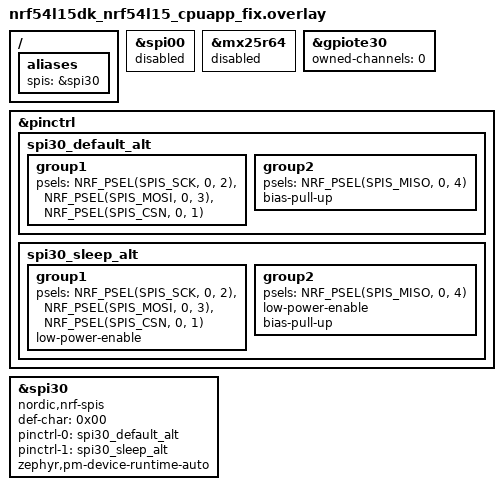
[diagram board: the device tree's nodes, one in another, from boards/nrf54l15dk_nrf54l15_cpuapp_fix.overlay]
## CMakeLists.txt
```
#
# Copyright (c) 2026 Nordic Semiconductor ASA
#
# SPDX-License-Identifier: LicenseRef-Nordic-5-Clause
#

cmake_minimum_required(VERSION 3.20.0)

find_package(Zephyr REQUIRED HINTS $ENV{ZEPHYR_BASE})

project(spis_floating)

target_sources(app PRIVATE src/main.c)
```

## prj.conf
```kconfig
CONFIG_SPI=y
CONFIG_SPI_PERIPHERAL=y

CONFIG_PM=y
CONFIG_PM_DEVICE=y
CONFIG_PM_DEVICE_RUNTIME=y

CONFIG_ASSERT=y

CONFIG_LOG=n
CONFIG_CONSOLE=n
CONFIG_UART_CONSOLE=n
CONFIG_SERIAL=n
CONFIG_BOOT_BANNER=n
CONFIG_NCS_BOOT_BANNER=n
```

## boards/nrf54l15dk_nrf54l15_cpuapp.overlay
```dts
/*
 * Copyright (c) 2026 Nordic Semiconductor ASA
 *
 * SPDX-License-Identifier: LicenseRef-Nordic-5-Clause
 */

/ {
	aliases {
		spis = &spi30;
	};
};

/* Disable mx25r64. */
&spi00 {
	status = "disabled";
};

&mx25r64 {
	status = "disabled";
};

&gpiote30 {
	status = "okay";
	owned-channels = <0>;
};

&pinctrl {
	spi30_default_alt: spi30_default_alt {
		group1 {
			psels = <NRF_PSEL(SPIS_SCK, 0, 2)>,	/* UART0_RTS */
				<NRF_PSEL(SPIS_MOSI, 0, 3)>,	/* UART0_CTS */
				<NRF_PSEL(SPIS_MISO, 0, 4)>,
				<NRF_PSEL(SPIS_CSN, 0, 1)>;	/* UART0_RX */
		};
	};

	spi30_sleep_alt: spi30_sleep_alt {
		group1 {
			psels = <NRF_PSEL(SPIS_SCK, 0, 2)>,
				<NRF_PSEL(SPIS_MOSI, 0, 3)>,
				<NRF_PSEL(SPIS_MISO, 0, 4)>,
				<NRF_PSEL(SPIS_CSN, 0, 1)>;
			low-power-enable;
		};
	};
};

&spi30 {
	compatible = "nordic,nrf-spis";
	status = "okay";
	def-char = <0x00>;
	pinctrl-0 = <&spi30_default_alt>;
	pinctrl-1 = <&spi30_sleep_alt>;
	pinctrl-names = "default", "sleep";
	/delete-property/ rx-delay-supported;
	/delete-property/ rx-delay;
	zephyr,pm-device-runtime-auto;
};
```

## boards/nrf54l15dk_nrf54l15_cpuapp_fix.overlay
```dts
/*
 * Copyright (c) 2026 Nordic Semiconductor ASA
 *
 * SPDX-License-Identifier: LicenseRef-Nordic-5-Clause
 */

/ {
	aliases {
		spis = &spi30;
	};
};

/* Disable mx25r64. */
&spi00 {
	status = "disabled";
};

&mx25r64 {
	status = "disabled";
};

&gpiote30 {
	status = "okay";
	owned-channels = <0>;
};

&pinctrl {
	spi30_default_alt: spi30_default_alt {
		group1 {
			psels = <NRF_PSEL(SPIS_SCK, 0, 2)>,	/* UART0_RTS */
				<NRF_PSEL(SPIS_MOSI, 0, 3)>,	/* UART0_CTS */
				<NRF_PSEL(SPIS_CSN, 0, 1)>;	/* UART0_RX */
		};

		group2 {
			psels = <NRF_PSEL(SPIS_MISO, 0, 4)>;
			bias-pull-up;
		};
	};

	spi30_sleep_alt: spi30_sleep_alt {
		group1 {
			psels = <NRF_PSEL(SPIS_SCK, 0, 2)>,
				<NRF_PSEL(SPIS_MOSI, 0, 3)>,
				<NRF_PSEL(SPIS_CSN, 0, 1)>;
			low-power-enable;
		};

		group2 {
			psels = <NRF_PSEL(SPIS_MISO, 0, 4)>;
			low-power-enable;
			bias-pull-up;
		};
	};
};

&spi30 {
	compatible = "nordic,nrf-spis";
	status = "okay";
	def-char = <0x00>;
	pinctrl-0 = <&spi30_default_alt>;
	pinctrl-1 = <&spi30_sleep_alt>;
	pinctrl-names = "default", "sleep";
	/delete-property/ rx-delay-supported;
	/delete-property/ rx-delay;
	zephyr,pm-device-runtime-auto;
};
```

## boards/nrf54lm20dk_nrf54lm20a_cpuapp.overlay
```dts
/*
 * Copyright (c) 2026 Nordic Semiconductor ASA
 *
 * SPDX-License-Identifier: LicenseRef-Nordic-5-Clause
 */

/ {
	aliases {
		spis = &spi30;
	};
};

/* Disable mx25r64. */
&spi00 {
	status = "disabled";
};

&mx25r64 {
	status = "disabled";
};

&gpiote30 {
	status = "okay";
	owned-channels = <0>;
};

&pinctrl {
	spi30_default_alt: spi30_default_alt {
		group1 {
			psels = <NRF_PSEL(SPIS_SCK, 0, 8)>,	/* UART0_RTS */
				<NRF_PSEL(SPIS_MOSI, 0, 9)>,	/* UART0_CTS */
				<NRF_PSEL(SPIS_MISO, 0, 1)>,
				<NRF_PSEL(SPIS_CSN, 0, 7)>;	/* UART0_RX */
		};
	};

	spi30_sleep_alt: spi30_sleep_alt {
		group1 {
			psels = <NRF_PSEL(SPIS_SCK, 0, 8)>,
				<NRF_PSEL(SPIS_MOSI, 0, 9)>,
				<NRF_PSEL(SPIS_MISO, 0, 1)>,
				<NRF_PSEL(SPIS_CSN, 0, 7)>;
			low-power-enable;
		};
	};
};

&spi30 {
	compatible = "nordic,nrf-spis";
	status = "okay";
	def-char = <0x00>;
	pinctrl-0 = <&spi30_default_alt>;
	pinctrl-1 = <&spi30_sleep_alt>;
	pinctrl-names = "default", "sleep";
	/delete-property/ rx-delay-supported;
	/delete-property/ rx-delay;
	zephyr,pm-device-runtime-auto;
};
```

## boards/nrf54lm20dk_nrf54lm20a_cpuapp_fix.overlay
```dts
/*
 * Copyright (c) 2026 Nordic Semiconductor ASA
 *
 * SPDX-License-Identifier: LicenseRef-Nordic-5-Clause
 */

/ {
	aliases {
		spis = &spi30;
	};
};

/* Disable mx25r64. */
&spi00 {
	status = "disabled";
};

&mx25r64 {
	status = "disabled";
};

&gpiote30 {
	status = "okay";
	owned-channels = <0>;
};

&pinctrl {
	spi30_default_alt: spi30_default_alt {
		group1 {
			psels = <NRF_PSEL(SPIS_SCK, 0, 8)>,	/* UART0_RTS */
				<NRF_PSEL(SPIS_MOSI, 0, 9)>,	/* UART0_CTS */
				<NRF_PSEL(SPIS_CSN, 0, 7)>;	/* UART0_RX */
		};

		group2 {
			psels = <NRF_PSEL(SPIS_MISO, 0, 1)>;
			bias-pull-up;
		};
	};

	spi30_sleep_alt: spi30_sleep_alt {
		group1 {
			psels = <NRF_PSEL(SPIS_SCK, 0, 8)>,
				<NRF_PSEL(SPIS_MOSI, 0, 9)>,
				<NRF_PSEL(SPIS_CSN, 0, 7)>;
			low-power-enable;
		};

		group2 {
			psels = <NRF_PSEL(SPIS_MISO, 0, 1)>;
			low-power-enable;
			bias-pull-up;
		};
	};
};

&spi30 {
	compatible = "nordic,nrf-spis";
	status = "okay";
	def-char = <0x00>;
	pinctrl-0 = <&spi30_default_alt>;
	pinctrl-1 = <&spi30_sleep_alt>;
	pinctrl-names = "default", "sleep";
	/delete-property/ rx-delay-supported;
	/delete-property/ rx-delay;
	zephyr,pm-device-runtime-auto;
};
```

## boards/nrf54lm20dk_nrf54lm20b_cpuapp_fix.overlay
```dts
#include "nrf54lm20dk_nrf54lm20a_cpuapp_fix.overlay"
```

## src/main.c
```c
/*
 * Copyright (c) 2026 Nordic Semiconductor ASA
 *
 * SPDX-License-Identifier: LicenseRef-Nordic-5-Clause
 */

#include <zephyr/kernel.h>
#include <zephyr/drivers/spi.h>

#define BUF_SIZE 32
static const struct device *spis_dev = DEVICE_DT_GET(DT_ALIAS(spis));
static const struct spi_config spis_config = {
	.operation = SPI_OP_MODE_PERIPHERAL | SPI_WORD_SET(8),
};

int main(void)
{
	bool status;
	static char rx_buffer[BUF_SIZE];
	struct spi_buf rx_spi_bufs = {.buf = rx_buffer, .len = sizeof(rx_buffer)};
	struct spi_buf_set rx_spi_buf_set = {.buffers = &rx_spi_bufs, .count = 1};

	status = device_is_ready(spis_dev);
	__ASSERT(status, "Error: SPI device is not ready");

	/* Arbitrary delay for CI purposes.
	 * Catch moment when device enters low power state.
	 */
	k_busy_wait(2000000);

	memset(rx_buffer, 0x00, sizeof(rx_buffer));

	/* No Controller device on the SPI bus -> spi_read() will never complete. */
	spi_read(spis_dev, &spis_config, &rx_spi_buf_set);
	k_msleep(2000);

	__ASSERT(false, "Code execution shall not get here.");

	return 0;
}
```
